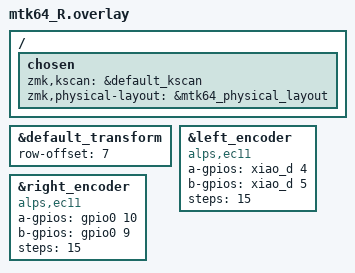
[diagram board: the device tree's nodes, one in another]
#include "mtk64.dtsi"

/ {
    chosen {
        zmk,kscan = &default_kscan;
        zmk,physical-layout = &mtk64_physical_layout;
    };
};

&default_transform {
    row-offset = <7>;
};

/*
&kscan0 {
    gpios
        = <&xiao_d 1 GPIO_ACTIVE_HIGH> 
        , <&xiao_d 2 GPIO_ACTIVE_HIGH> 
        , <&xiao_d 3 GPIO_ACTIVE_HIGH> 
        , <&xiao_d 6 GPIO_ACTIVE_HIGH>
        , <&xiao_d 7 GPIO_ACTIVE_HIGH> 
        , <&xiao_d 8 GPIO_ACTIVE_HIGH> 
        , <&xiao_d 9 GPIO_ACTIVE_HIGH> 	
    ;
};
*/

&left_encoder {
    status = "okay";
};

&right_encoder {
    status = "okay";
};

&left_encoder {
    compatible = "alps,ec11";
    a-gpios = <&xiao_d 4 (GPIO_ACTIVE_HIGH | GPIO_PULL_UP)>;
    b-gpios = <&xiao_d 5 (GPIO_ACTIVE_HIGH | GPIO_PULL_UP)>;
    steps = <15>;
    status = "okay";
};

&right_encoder {
    compatible = "alps,ec11";
    a-gpios = <&gpio0 10 (GPIO_ACTIVE_HIGH | GPIO_PULL_UP)>;
    b-gpios = <&gpio0 9  (GPIO_ACTIVE_HIGH | GPIO_PULL_UP)>;
    steps = <15>;
    status = "okay";
};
